VERSION ""

NS_ :

BS_:

BU_:

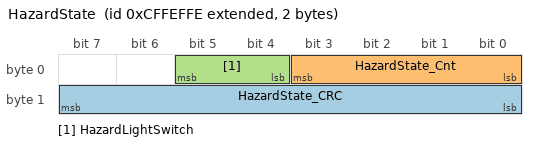
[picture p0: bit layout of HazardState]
BO_ 2365583358 HazardState: 2 Vector__XXX
 SG_ HazardState_CRC : 8|8@1+ (1,0) [0|0] "" Vector__XXX
 SG_ HazardState_Cnt : 0|4@1+ (1,0) [0|0] "" Vector__XXX
 SG_ HazardLightSwitch : 4|2@1+ (1,0) [0|3] "" Vector__XXX

CM_ "$File: //depot/auto/dbc/Software_Modules/Exterior_Lights/HazardSwitch/0.0.3.0/HazardSwitch.dbc $
$Change: 215977 $
$DateTime: 2024/08/21 10:06:51 $
$Revision: #1 $";
CM_ BO_ 2365583358 "Operators External Light Controls Message
The message containing the information about the position of the operator's external light control switch(s).  Including switches for the Headlights, turn signals, hazard light, clearance lights, marker ...";
CM_ SG_ 2365583358 HazardLightSwitch "A 2 bit parameter to indicate the selected position of the operator's hazard light switch.

00   Hazard Lamps to be Off
01   Hazard Lamps to be Flashing
10   Error
11   Not available (do not change)";
BA_DEF_  "DBName" STRING ;
BA_DEF_ SG_  "SigType" ENUM  "Default","Range","RangeSigned","ASCII","Discrete","Control","ReferencePGN","DTC","StringDelimiter","StringLength","StringLengthControl","MessageCounter","MessageChecksum";
BA_DEF_ SG_  "GenSigSendType" ENUM  "Cyclic","OnWrite","OnWriteWithRepetition","OnChange","OnChangeWithRepetition","IfActive","IfActiveWithRepetition","NoSigSendType";
BA_DEF_ SG_  "GenSigILSupport" ENUM  "No","Yes";
BA_DEF_ SG_  "GenSigEVName" STRING ;
BA_DEF_ SG_  "SPN" INT 0 524287;
BA_DEF_ BO_  "GenMsgILSupport" ENUM  "No","Yes";
BA_DEF_ BO_  "GenMsgDelayTime" INT 0 1000;
BA_DEF_ BO_  "GenMsgRequestable" INT 0 1;
BA_DEF_ BO_  "GenMsgSendType" ENUM  "cyclic","NotUsed","NotUsed","NotUsed","NotUsed","NotUsed","NotUsed","IfActive","noMsgSendType";
BA_DEF_ BO_  "VFrameFormat" ENUM  "StandardCAN","ExtendedCAN","reserved","J1939PG";
BA_DEF_ BO_  "GenMsgCycleTime" INT 0 3600000;
BA_DEF_ BO_  "SendOnChange" ENUM  "No","Yes";
BA_DEF_ BO_  "Producer" STRING ;
BA_DEF_ BU_  "NmStationAddress" INT 0 255;
BA_DEF_  "SAE_J1939_DA_SpecVersion" STRING ;
BA_DEF_  "SAE_J1939_81_SpecVersion" STRING ;
BA_DEF_  "DatabaseVersion" STRING ;
BA_DEF_  "BusType" STRING ;
BA_DEF_  "ProtocolType" STRING ;
BA_DEF_  "SAE_J1939_75_SpecVersion" STRING ;
BA_DEF_  "SAE_J1939_21_SpecVersion" STRING ;
BA_DEF_  "SAE_J1939_73_SpecVersion" STRING ;
BA_DEF_  "SAE_J1939_71_SpecVersion" STRING ;
BA_DEF_DEF_  "DBName" "";
BA_DEF_DEF_  "SigType" "Default";
BA_DEF_DEF_  "GenSigSendType" "NoSigSendType";
BA_DEF_DEF_  "GenSigILSupport" "Yes";
BA_DEF_DEF_  "GenSigEVName" "Env@Nodename_@Signame";
BA_DEF_DEF_  "SPN" 0;
BA_DEF_DEF_  "GenMsgILSupport" "Yes";
BA_DEF_DEF_  "GenMsgDelayTime" 0;
BA_DEF_DEF_  "GenMsgRequestable" 1;
BA_DEF_DEF_  "GenMsgSendType" "noMsgSendType";
BA_DEF_DEF_  "VFrameFormat" "J1939PG";
BA_DEF_DEF_  "GenMsgCycleTime" 0;
BA_DEF_DEF_  "SendOnChange" "No";
BA_DEF_DEF_  "NmStationAddress" 254;
BA_DEF_DEF_  "SAE_J1939_DA_SpecVersion" "";
BA_DEF_DEF_  "SAE_J1939_81_SpecVersion" "";
BA_DEF_DEF_  "DatabaseVersion" "";
BA_DEF_DEF_  "BusType" "";
BA_DEF_DEF_  "ProtocolType" "";
BA_DEF_DEF_  "SAE_J1939_75_SpecVersion" "";
BA_DEF_DEF_  "SAE_J1939_21_SpecVersion" "";
BA_DEF_DEF_  "SAE_J1939_73_SpecVersion" "";
BA_DEF_DEF_  "SAE_J1939_71_SpecVersion" "";
BA_ "SAE_J1939_71_SpecVersion" "2012-10";
BA_ "SAE_J1939_73_SpecVersion" "2012-10";
BA_ "SAE_J1939_21_SpecVersion" "2006-10";
BA_ "SAE_J1939_75_SpecVersion" "2012-05";
BA_ "ProtocolType" "J1939";
BA_ "BusType" "CAN";
BA_ "DatabaseVersion" "8.5";
BA_ "SAE_J1939_81_SpecVersion" "2012-05";
BA_ "SAE_J1939_DA_SpecVersion" "2015-01";
BA_ "DBName" "HazSw";
BA_ "SendOnChange" BO_ 2365583358 1;
BA_ "GenMsgCycleTime" BO_ 2365583358 1000;
BA_ "GenMsgSendType" BO_ 2365583358 0;
BA_ "GenMsgDelayTime" BO_ 2365583358 100;
BA_ "SigType" SG_ 2365583358 HazardState_CRC 12;
BA_ "SigType" SG_ 2365583358 HazardState_Cnt 11;
BA_ "SPN" SG_ 2365583358 HazardLightSwitch 2875;
BA_ "SigType" SG_ 2365583358 HazardLightSwitch 4;
BA_ "Producer" BO_ 2365583358 "UICS";
VAL_ 2365583358 HazardLightSwitch 3 "Not available" 2 "Error" 1 "Hazard Lamps to be Flashing" 0 "Hazard Lamps to be Off" ;
